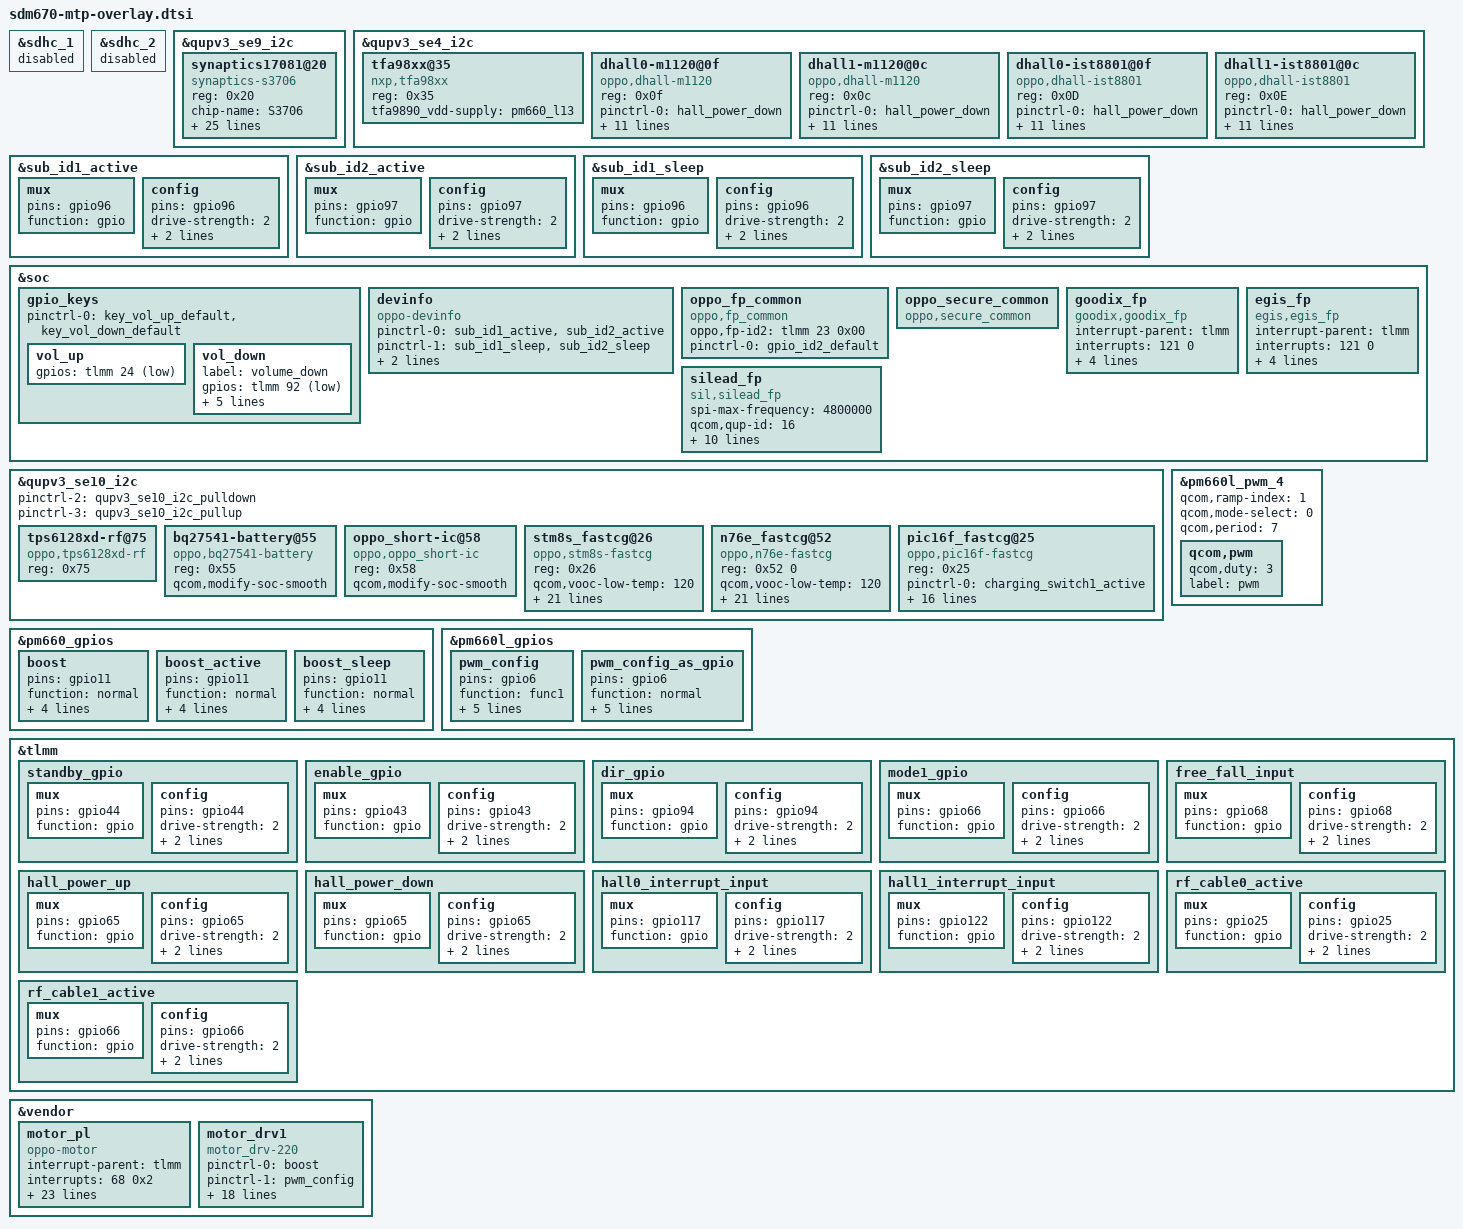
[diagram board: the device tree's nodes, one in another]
&sdhc_1 {
    status = "disabled";
};

&sdhc_2 {
    status = "disabled";
};

&qupv3_se9_i2c  {
    status = "okay";
    synaptics17081@20 {
        compatible = "synaptics-s3706";
        reg = <0x20>;
        chip-name = "S3706";

        /* Interrupt && Irq-gpio */
        interrupt-parent = <&tlmm>;
        interrupts = <125 0x00>;

        /* Power Config */
        enable2v8_gpio = <&pm660_gpios 13 0x1>;
        //vdd_2v8-supply = <&pm660l_l2>;
        vcc_1v8-supply = <&pm660_l8>;
        //vdd_2v8_volt = <2960000>;

        /* Other HW Resource */
        irq-gpio = <&tlmm 125 0x2008>;
        reset-gpio = <&tlmm 119 0x1>; //use gpio 199 for evt
        pinctrl-names = "default";
        pinctrl-0 = <&ts_int_active &ts_reset_active>;

        touchpanel,max-num-support = <10>;
        touchpanel,tx-rx-num = <16 34>;
        touchpanel,panel-coords = <1080 2340>;
        touchpanel,display-coords = <1080 2340>;
        touchpanel,touchmajor-limit = <0 54>;

        /* SW Support Feature Control */
        black_gesture_support;
        fw_edge_limit_support;
        fw_corner_limit_support;
        //spurious_fingerprint_support;
        charger_pump_support;
        game_switch_support;
        face_detect_support;
        smart_gesture_support;
        pressure_report_support;
        fw_update_app_support;
        fingerprint_underscreen_support;
        ic_is_synaptics;

        /*
         *Virtual Key Config:
         *1:touchpanel,button-type: <virtualkey_type  supportted_button-map>
         *virtualkey_type:
         *Type 1: using board_properties
         *Type 2: using same IC (button zone&& touch zone are seprate)
         *Type 3: using diffrent IC (button zone&& touch zone are seprate)
         *Type 4: No need of virtual key process
         *supportted_button-map:select|menu|home|back
         *
         *2:touchpanel,button-map
         *type (X1,Y1)(X2,Y2)(X3,Y3)(Width_X,Hight_Y)--Only when button-type is 0
         */
        touchpanel,button-type = <4>;
        touchpanel.button-TRx = <0 0>;
    };
};

&qupv3_se4_i2c {
    status = "okay";
    tfa98xx@35 {
        compatible = "nxp,tfa98xx";
        reg = <0x35>;
        //nxp,rst-ctrl-gpio = <&tlmm 80 0x00>;
        tfa9890_vdd-supply = <&pm660_l13>;
        status = "okay";
    };
};

&sub_id1_active {
        mux {
            pins = "gpio96";
            function = "gpio";
        };
        config {
            pins = "gpio96";
            drive-strength = <2>;
            bias-pull-up;
            input-enable;
        };
};

&sub_id2_active {
        mux {
            pins = "gpio97";
            function = "gpio";
        };
        config {
            pins = "gpio97";
            drive-strength = <2>;
            bias-pull-up;
            input-enable;
        };
};

&sub_id1_sleep {
        mux {
            pins = "gpio96";
            function = "gpio";
        };
        config {
            pins = "gpio96";
            drive-strength = <2>;
            input-enable;
            bias-disable;
        };
};
&sub_id2_sleep {
        mux {
            pins = "gpio97";
            function = "gpio";
        };
        config {
            pins = "gpio97";
            drive-strength = <2>;
            input-enable;
            bias-disable;
        };
};

&soc {
    gpio_keys {
	        pinctrl-0 = < &key_vol_up_default
	                &key_vol_down_default>;

            /delete-node/ cam_snapshot;
            /delete-node/ cam_focus;

            vol_up {
                gpios = <&tlmm 24 GPIO_ACTIVE_LOW>;
            };

            vol_down {
                label = "volume_down";
                gpios = <&tlmm 92 GPIO_ACTIVE_LOW>;
                linux,input-type = <1>;
                linux,code = <114>;
                gpio-key,wakeup;
                debounce-interval = <15>;
                linux,can-disable;
            };
    };

    devinfo {
        compatible = "oppo-devinfo";
        pinctrl-names = "sub_id_active","sub_id_sleep";
        pinctrl-0 = <&sub_id1_active &sub_id2_active>;
        pinctrl-1 = <&sub_id1_sleep &sub_id2_sleep>;
        sub_id1-gpio = <&tlmm 96 0>;
        sub_id2-gpio = <&tlmm 97 0>;
    };

    oppo_fp_common { //Slave driver and CS ID
            compatible = "oppo,fp_common"; //Manufacture, and Model
            oppo,fp-id2 = <&tlmm 23 0x00>; // 0: silead,1:goodix
            pinctrl-names = "default";
            pinctrl-0 = <&gpio_id2_default>;
    };

    oppo_secure_common {
        compatible = "oppo,secure_common";
    };

    goodix_fp {
        compatible = "goodix,goodix_fp";
        interrupt-parent = <&tlmm>;
        interrupts = <121 0>;
        goodix,gpio_irq = <&tlmm 121 0x1>;
        goodix,gpio_reset = <&tlmm 80 0x0>;
        ldo5-supply = <&pm660l_l5>; // pm660l_l5 for goodix_fp
        pinctrl-names = "default";
        pinctrl-0 = <&gpio_goodix_irq_default>;
    };

    egis_fp {
        compatible = "egis,egis_fp";
        interrupt-parent = <&tlmm>;
        interrupts = <121 0>;
        egis,gpio_irq = <&tlmm 121 0x1>;
        egis,gpio_reset = <&tlmm 80 0x0>;
        ldo5-supply = <&pm660l_l5>; // pm660l_l5 for egis
        pinctrl-names = "default";
        pinctrl-0 = <&gpio_egis_irq_default>;
    };

    silead_fp {
        compatible = "sil,silead_fp";
        spi-max-frequency = <4800000>;
        qcom,qup-id = <16>;
        interrupt-parent = <&tlmm>;
        interrupts = <121 0>;
        avdd-supply = <&pm660l_l5>;
        pinctrl-names = "pmx_silfp_active","pmx_silfp_suspend","pmx_silfp_release";
        pinctrl-0 = <&silfp_int_active &silfp_reset_active>;
        pinctrl-1 = <&silfp_int_suspend &silfp_reset_suspend>;
        pinctrl-2 = <&silfp_release>;
        rst-gpios = <&tlmm 80 0x0>;
        irq-gpios = <&tlmm 121 0x1>;
    };
};

&qupv3_se10_i2c {
    status = "okay";
    pinctrl-names = "default", "sleep", "pulldown", "pullup";
    pinctrl-2 = <&qupv3_se10_i2c_pulldown>;
    pinctrl-3 = <&qupv3_se10_i2c_pullup>;

    tps6128xd-rf@75 {
        status = "okay";
        compatible = "oppo,tps6128xd-rf";
        reg = <0x75>;
    };
    bq27541-battery@55 {
        status = "okay";
        compatible = "oppo,bq27541-battery";
        reg = <0x55>;
        qcom,modify-soc-smooth;
    };

    oppo_short-ic@58 {
        status = "okay";
        compatible = "oppo,oppo_short-ic";
        reg = <0x58>;
        qcom,modify-soc-smooth;
    };

    stm8s_fastcg@26{
        status = "okay";
        compatible = "oppo,stm8s-fastcg";
        reg = <0x26>;
        qcom,vooc-low-temp = <120>;
        qcom,oppo_batt_4400mv;
        qcom,vooc-fw-type = <8>;
        qcom,vooc_fw_update_newmethod;

        pinctrl-names = "switch1_act_switch2_act", "switch1_sleep_switch2_sleep",
                        "switch1_act_switch3_act", "switch1_sleep_switch3_sleep",
                        "switch1_act_switch2_sleep", "switch1_sleep_switch2_act",
                        "clock_active","clock_sleep",
                        "data_active","data_sleep",
                        "reset_active","reset_sleep",
                        "vooc_mcu_id_default";
        pinctrl-0 = <&charging_switch1_active>;
        pinctrl-1 = <&charging_switch1_sleep >;
        pinctrl-2 = <&charging_switch1_active>;
        pinctrl-3 = <&charging_switch1_sleep >;
        pinctrl-4 = <&charging_switch1_active>;
        pinctrl-5 = <&charging_switch1_sleep>;
        pinctrl-6 = <&charging_clock_active >;
        pinctrl-7 = <&charging_clock_sleep >;
        pinctrl-8 = <&charging_data_active >;
        pinctrl-9 = <&charging_data_sleep >;
        pinctrl-10 = <&charging_reset_active >;
        pinctrl-11 = <&charging_reset_sleep >;
        pinctrl-12 = <&vooc_mcu_id_default>;

        qcom,charging_switch1-gpio = <&tlmm 40 0x00>;
        //qcom,charging_switch2-gpio = <&tlmm 113 0x00>;
        //qcom,charging_switch3-gpio = <&tlmm 38 0x00>;

        qcom,charging_reset-gpio = <&tlmm 91 0x00>;
        qcom,charging_clock-gpio = <&tlmm 124 0x00>;
        qcom,charging_data-gpio = <&tlmm 123 0x00>;
        qcom,vooc_mcu_id-gpio = <&tlmm 116 0x00>;
    };

    n76e_fastcg@52{
        status = "okay";
        compatible = "oppo,n76e-fastcg";
        reg = <0x52 0>;
        qcom,vooc-low-temp = <120>;
        qcom,oppo_batt_4400mv;
        qcom,vooc-fw-type = <2>;
        qcom,vooc_fw_update_newmethod;

        pinctrl-names = "switch1_act_switch2_act", "switch1_sleep_switch2_sleep",
                        "switch1_act_switch3_act", "switch1_sleep_switch3_sleep",
                        "switch1_act_switch2_sleep", "switch1_sleep_switch2_act",
                        "clock_active","clock_sleep",
                        "data_active","data_sleep",
                        "reset_active","reset_sleep",
                        "vooc_mcu_id_default";
        pinctrl-0 = <&charging_switch1_active>;
        pinctrl-1 = <&charging_switch1_sleep>;
        pinctrl-2 = <&charging_switch1_active>;
        pinctrl-3 = <&charging_switch1_sleep>;
        pinctrl-4 = <&charging_switch1_active>;
        pinctrl-5 = <&charging_switch1_sleep>;
        pinctrl-6 = <&charging_clock_active>;
        pinctrl-7 = <&charging_clock_sleep>;
        pinctrl-8 = <&charging_data_active>;
        pinctrl-9 = <&charging_data_sleep>;
        pinctrl-10 = <&charging_reset_active>;
        pinctrl-11 = <&charging_reset_sleep>;
        pinctrl-12 = <&vooc_mcu_id_default>;

        qcom,charging_switch1-gpio = <&tlmm 40 0x00>;
        //qcom,charging_switch2-gpio = <&tlmm 113 0x00>;
        //qcom,charging_switch3-gpio = <&tlmm 38 0x00>;

        qcom,charging_reset-gpio = <&tlmm 91 0x00>;
        qcom,charging_clock-gpio = <&tlmm 124 0x00>;
        qcom,charging_data-gpio = <&tlmm 123 0x00>;
        qcom,vooc_mcu_id-gpio = <&tlmm 116 0x00>;
    };

    pic16f_fastcg@25{
        status = "okay";
        compatible = "oppo,pic16f-fastcg";
        reg = <0x25>;

        pinctrl-names = "switch1_act_switch2_act", "switch1_sleep_switch2_sleep",
                        "switch1_act_switch3_act", "switch1_sleep_switch3_sleep",
                        "switch1_act_switch2_sleep", "switch1_sleep_switch2_act",
                        "clock_active","clock_sleep",
                        "data_active","data_sleep",
                        "reset_active","reset_sleep",
                        "vooc_mcu_id_default";
        pinctrl-0 = <&charging_switch1_active>;
        pinctrl-1 = <&charging_switch1_sleep >;
        pinctrl-2 = <&charging_switch1_active>;
        pinctrl-3 = <&charging_switch1_sleep >;
        pinctrl-4 = <&charging_switch1_active>;
        pinctrl-5 = <&charging_switch1_sleep>;
        pinctrl-6 = <&charging_clock_active >;
        pinctrl-7 = <&charging_clock_sleep >;
        pinctrl-8 = <&charging_data_active >;
        pinctrl-9 = <&charging_data_sleep >;
        pinctrl-10 = <&charging_reset_active >;
        pinctrl-11 = <&charging_reset_sleep >;
        pinctrl-12 = <&vooc_mcu_id_default>;

        qcom,charging_switch1-gpio = <&tlmm 40 0x00>;
        //qcom,charging_switch2-gpio = <&tlmm 113 0x00>;
        //qcom,charging_switch3-gpio = <&tlmm 38 0x00>;

        qcom,charging_reset-gpio = <&tlmm 91 0x00>;
        qcom,charging_clock-gpio = <&tlmm 124 0x00>;
        qcom,charging_data-gpio = <&tlmm 123 0x00>;
        //qcom,vooc_mcu_id-gpio = <&tlmm 42 0x00>;
    };
};

&qupv3_se4_i2c {
    status = "okay";
    dhall0-m1120@0f {
        compatible = "oppo,dhall-m1120";
        reg = <0x0f>;
        pinctrl-names = "hall_power_down","hall_power_up","hall0_interrupt_input";
        pinctrl-0 = <&hall_power_down>;
        pinctrl-1 = <&hall_power_up>;
        pinctrl-2 = <&hall0_interrupt_input>;
        interrupt-parent = <&tlmm>;
        interrupts = <117 0x2>;
        dhall,irq-gpio = <&tlmm 117 0x2008>;
        dhall,id = <0>;
        vdd_2v8-supply = <&pm660l_l3>;//VREG_L3B_3P0
        vcc_1v8-supply = <&pm660_l14>;//VREG_L14A_1P8
        qcom,hall-power-gpio = <&tlmm 65 0>;
        hall,bias_support;
        hall,bias-ratio = <80>;// current/goal *100
    };

    dhall1-m1120@0c {
        compatible = "oppo,dhall-m1120";
        reg = <0x0c>;
        pinctrl-names = "hall_power_down","hall_power_up","hall1_interrupt_input";
        pinctrl-0 = <&hall_power_down>;
        pinctrl-1 = <&hall_power_up>;
        pinctrl-2 = <&hall1_interrupt_input>;
        interrupt-parent = <&tlmm>;
        interrupts = <122 0x2>;
        dhall,irq-gpio = <&tlmm 122 0x2008>;
        dhall,id = <1>;
        vdd_2v8-supply = <&pm660l_l3>;//VREG_L19A_3P0
        vcc_1v8-supply = <&pm660_l14>;//VREG_S4A_1P8
        qcom,hall-power-gpio = <&tlmm 65 0>;
        hall,bias_support;
        hall,bias-ratio = <80>;// current/goal *100
    };

    dhall0-ist8801@0f {
        compatible = "oppo,dhall-ist8801";
        reg = <0x0D>;
        pinctrl-names = "hall_power_down","hall_power_up","hall0_interrupt_input";
        pinctrl-0 = <&hall_power_down>;
        pinctrl-1 = <&hall_power_up>;
        pinctrl-2 = <&hall0_interrupt_input>;
        interrupt-parent = <&tlmm>;
        interrupts = <117 0x2>;
        dhall,irq-gpio = <&tlmm 117 0x2008>;
        dhall,id = <0>;
        vdd_2v8-supply = <&pm660l_l3>;//VREG_L3B_3P0
        vcc_1v8-supply = <&pm660_l14>;//VREG_L14A_1P8
        qcom,hall-power-gpio = <&tlmm 65 0>;
        hall,bias_support;
        hall,bias-ratio = <80>;// current/goal *100
    };

    dhall1-ist8801@0c {
        compatible = "oppo,dhall-ist8801";
        reg = <0x0E>;
        pinctrl-names = "hall_power_down","hall_power_up","hall1_interrupt_input";
        pinctrl-0 = <&hall_power_down>;
        pinctrl-1 = <&hall_power_up>;
        pinctrl-2 = <&hall1_interrupt_input>;
        interrupt-parent = <&tlmm>;
        interrupts = <122 0x2>;
        dhall,irq-gpio = <&tlmm 122 0x2008>;
        dhall,id = <1>;
        vdd_2v8-supply = <&pm660l_l3>;//VREG_L19A_3P0
        vcc_1v8-supply = <&pm660_l14>;//VREG_S4A_1P8
        qcom,hall-power-gpio = <&tlmm 65 0>;
        hall,bias_support;
        hall,bias-ratio = <80>;// current/goal *100
    };
};

&pm660_gpios {
    boost: boost {
        pins = "gpio11";
        function = "normal";
        bias-pull-down; //pull down
        power-source = <0>; // VIN0,1.8V
        output-low; //digital output, no invert
        qcom,drive-strength = <3>;//0.15
    };

    boost_active:boost_active {
        pins = "gpio11";
        function = "normal";
        bias-disable; //pull down
        power-source = <0>; // VIN0,1.8V
        output-high; //digital output, no invert
        qcom,drive-strength = <3>;//0.15
    };

    boost_sleep:boost_sleep {
        pins = "gpio11";
        function = "normal";
        bias-pull-down; //pull down
        power-source = <0>; // VIN0,1.8V
        output-low; //digital output, no invert
        qcom,drive-strength = <3>;//0.15
    };
};

&pm660l_gpios {
    //pwm mode
    pwm_config: pwm_config {
        pins = "gpio6";//GPIO 8
        function = "func1";//Special Function 1,pwm
        bias-disable; //No Pull
        power-source = <0>;//VIN0
        output-low; //digital output, no invert
        qcom,drive-strength = <3>; //LOW strength
        drive-push-pull;//CMOS
    };
    //gpio mode for stspin220
    pwm_config_as_gpio: pwm_config_as_gpio {
        pins = "gpio6";//GPIO 8
        function = "normal";//
        bias-disable; //No Pull
        power-source = <0>;//VIN0
        output-low; //digital output, no invert
        qcom,drive-strength = <3>; //LOW strength
        drive-push-pull;//CMOS
    };
};

&pm660l_pwm_4 {
    qcom,ramp-index = <1>;
    //qcom,force-pwm-size = <9>;
    qcom,mode-select = <0>; /* PWM */
    qcom,period = <7>;
    #pwm-cells = <2>;
    status = "okay";
    qcom,pwm {
        qcom,duty = <3>;
        label = "pwm";
    };
};

&tlmm {
    standby_gpio: standby_gpio {
        mux {
            pins = "gpio44";
            function = "gpio";
        };
        config {
            pins = "gpio44";
            drive-strength = <2>;
            bias-disable;
            output-low;
        };
    };

    enable_gpio: enable_gpio {
        mux {
            pins = "gpio43";
            function = "gpio";
        };
        config {
            pins = "gpio43";
            drive-strength = <2>;
            bias-disable;
            output-low;
        };
    };

    dir_gpio: dir_gpio {
        mux {
            pins = "gpio94";
            function = "gpio";
        };
        config {
            pins = "gpio94";
            drive-strength = <2>;
            bias-disable;
            output-low;
        };
    };

    mode1_gpio: mode1_gpio {
        mux {
            pins = "gpio66";
            function = "gpio";
        };
        config {
            pins = "gpio66";
            drive-strength = <2>;
            bias-disable;
            output-low;
        };
    };
    free_fall_input: free_fall_input {
        mux {
            pins = "gpio68";
            function = "gpio";
        };

        config {
            pins = "gpio68";
            drive-strength = <2>;
            input-enable;
            bias-disable; //No Pull
        };
    };

    hall_power_up: hall_power_up {
        mux {
            pins = "gpio65";
            function = "gpio";
        };

        config {
            pins = "gpio65";
            drive-strength = <2>;
            output-high;
            bias-pull-down;
        };
    };
    hall_power_down: hall_power_down {
        mux {
            pins = "gpio65";
            function = "gpio";
        };

        config {
            pins = "gpio65";
            drive-strength = <2>;
            output-low;
            bias-pull-down;
        };
    };
    hall0_interrupt_input: hall0_interrupt_input {
        mux {
            pins = "gpio117";
            function = "gpio";
        };

        config {
            pins = "gpio117";
            drive-strength = <2>;
            input-enable;
            bias-pull-up; //Pull up
        };
    };
    hall1_interrupt_input: hall1_interrupt_input {
        mux {
            pins = "gpio122";
            function = "gpio";
        };

        config {
            pins = "gpio122";
            drive-strength = <2>;
            input-enable;
            bias-pull-up; //Pull up
        };
    };

    rf_cable0_active: rf_cable0_active {
        mux {
            pins = "gpio25";
            function = "gpio";
        };
        config {
            pins = "gpio25";
            drive-strength = <2>;
            input-enable;
            bias-pull-up;
        };
    };

    rf_cable1_active: rf_cable1_active {
        mux {
            pins = "gpio66";
            function = "gpio";
        };
        config {
            pins = "gpio66";
            drive-strength = <2>;
            input-enable;
            bias-pull-up;
        };
    };
};

&vendor  {
    motor_pl: motor_pl {
        compatible = "oppo-motor";
        interrupt-parent = <&tlmm>;
        interrupts = <68 0x2>;
        motor,irq-gpio = <&tlmm 68 0x2008>;
        pinctrl-names = "free_fall_input";
        pinctrl-0 = <&free_fall_input>;
        hall-irq-pos = <170>;
        motor-retard-pos = <430>;
        delay-cycle = <14 14 14>; //ms
        slow-delay-cycle = <28 28 28>; //ms
        full-speed-param = <65 12000>;
        up-speed-param = <5 12000>;
        down-speed-param = <3 156250>;
        nodetect-speed-param = <15 12000>;
        slow-full-speed-param = <60 31250>;
        slow-up-speed-param = <5 104166>;
        slow-down-speed-param = <3 156250>;
        slow-nodetect-speed-param = <15 104166>;
        stop-neg-point = <3 3>;
        stop-pos-point = <3 3>;
        pos-change-thrd = <300 350>;
        hall-data-sign = <0>;//1 represent positive ,0 represent negative
        press-irq-makeup = <0x37 0x37>;
        stop-retry = <0x4>;
        stop_in_advance;
        /*
        support mag noise decrease:
        511 - pattern[0] = irq_max
        pattern[1] - 512 = irq_min
        511 - pattern[2] = normal_max
        pattern[3] - 512 = normal_min
        average = 200
        */
        mag_noise_support;
        mag_noise_pattern = <80 400 0 662 200 100 100>;
    };

    motor_drv1: motor_drv1 {
        compatible = "motor_drv-220";
        pinctrl-names = "boost","pwm_config","pwm_config_as_gpio","enable_gpio","dir_gpio","standby_gpio","mode1_gpio","motor_active","motor_sleep";
        pinctrl-0 = <&boost>;
        pinctrl-1 = <&pwm_config>;
        pinctrl-2 = <&pwm_config_as_gpio>;
        pinctrl-3 = <&enable_gpio>;
        pinctrl-4 = <&dir_gpio>;
        pinctrl-5 = <&standby_gpio>;
        pinctrl-6 = <&mode1_gpio>;
        pinctrl-7 = <&boost_active>;
        pinctrl-8 = <&boost_sleep>;
        pwms = <&pm660l_pwm_4 0 0>;
        boost-gpio = <&pm660_gpios 11 0x00>;
        standby-gpio = <&tlmm 44 0>;
        dir-gpio = <&tlmm 94 0>;
        enable-gpio =  <&tlmm 43 0>;
        step-gpio = <&pm660l_gpios 6 0>;
        mode1-gpio = <&tlmm 66 0>;
            ratio-a = <24>;
        ratio-b = <1840>;//18.40
        ratio-c = <20>;
        ratio-d = <32>;
    };
};
